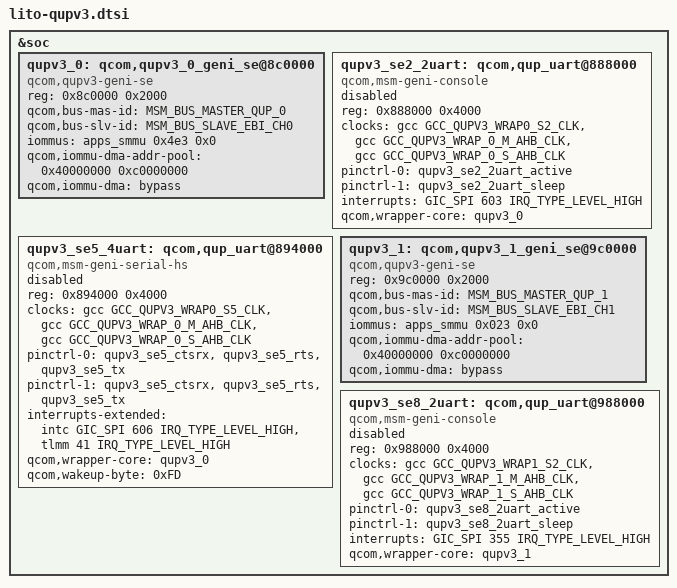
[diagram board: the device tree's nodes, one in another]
// SPDX-License-Identifier: GPL-2.0-only
/*
 * Copyright (c) 2018-2019, The Linux Foundation. All rights reserved.
 */

#include <dt-bindings/msm/msm-bus-ids.h>

&soc {
	/*QUPv3_0 */
	qupv3_0: qcom,qupv3_0_geni_se@8c0000 {
		compatible = "qcom,qupv3-geni-se";
		reg = <0x8c0000 0x2000>;
		qcom,bus-mas-id = <MSM_BUS_MASTER_QUP_0>;
		qcom,bus-slv-id = <MSM_BUS_SLAVE_EBI_CH0>;
		iommus = <&apps_smmu 0x4e3 0x0>;
		qcom,iommu-dma-addr-pool = <0x40000000 0xc0000000>;
		qcom,iommu-dma = "bypass";
	};

	/* Debug UART Instance for RUMI platform */
	qupv3_se2_2uart: qcom,qup_uart@888000 {
		compatible = "qcom,msm-geni-console";
		reg = <0x888000 0x4000>;
		reg-names = "se_phys";
		clock-names = "se-clk", "m-ahb", "s-ahb";
		clocks = <&gcc GCC_QUPV3_WRAP0_S2_CLK>,
			<&gcc GCC_QUPV3_WRAP_0_M_AHB_CLK>,
			<&gcc GCC_QUPV3_WRAP_0_S_AHB_CLK>;
		pinctrl-names = "default", "sleep";
		pinctrl-0 = <&qupv3_se2_2uart_active>;
		pinctrl-1 = <&qupv3_se2_2uart_sleep>;
		interrupts = <GIC_SPI 603 IRQ_TYPE_LEVEL_HIGH>;
		qcom,wrapper-core = <&qupv3_0>;
		status = "disabled";
	};

	/* 4-wire UART */
	qupv3_se5_4uart: qcom,qup_uart@894000 {
		compatible = "qcom,msm-geni-serial-hs";
		reg = <0x894000 0x4000>;
		reg-names = "se_phys";
		clock-names = "se-clk", "m-ahb", "s-ahb";
		clocks = <&gcc GCC_QUPV3_WRAP0_S5_CLK>,
			<&gcc GCC_QUPV3_WRAP_0_M_AHB_CLK>,
			<&gcc GCC_QUPV3_WRAP_0_S_AHB_CLK>;
		pinctrl-names = "default", "sleep";
		pinctrl-0 = <&qupv3_se5_ctsrx>, <&qupv3_se5_rts>,
						<&qupv3_se5_tx>;
		pinctrl-1 = <&qupv3_se5_ctsrx>, <&qupv3_se5_rts>,
						<&qupv3_se5_tx>;
		interrupts-extended = <&intc GIC_SPI 606 IRQ_TYPE_LEVEL_HIGH>,
				<&tlmm 41 IRQ_TYPE_LEVEL_HIGH>;
		qcom,wrapper-core = <&qupv3_0>;
		qcom,wakeup-byte = <0xFD>;
		status = "disabled";
	};

	/*QUPv3_1 */
	qupv3_1: qcom,qupv3_1_geni_se@9c0000 {
		compatible = "qcom,qupv3-geni-se";
		reg = <0x9c0000 0x2000>;
		qcom,bus-mas-id = <MSM_BUS_MASTER_QUP_1>;
		qcom,bus-slv-id = <MSM_BUS_SLAVE_EBI_CH1>;
		iommus = <&apps_smmu 0x023 0x0>;
		qcom,iommu-dma-addr-pool = <0x40000000 0xc0000000>;
		qcom,iommu-dma = "bypass";
	};

	/* 2-wire UART */
	qupv3_se8_2uart: qcom,qup_uart@988000 {
		compatible = "qcom,msm-geni-console";
		reg = <0x988000 0x4000>;
		reg-names = "se_phys";
		clock-names = "se-clk", "m-ahb", "s-ahb";
		clocks = <&gcc GCC_QUPV3_WRAP1_S2_CLK>,
			<&gcc GCC_QUPV3_WRAP_1_M_AHB_CLK>,
			<&gcc GCC_QUPV3_WRAP_1_S_AHB_CLK>;
		pinctrl-names = "default", "sleep";
		pinctrl-0 = <&qupv3_se8_2uart_active>;
		pinctrl-1 = <&qupv3_se8_2uart_sleep>;
		interrupts = <GIC_SPI 355 IRQ_TYPE_LEVEL_HIGH>;
		qcom,wrapper-core = <&qupv3_1>;
		status = "disabled";
	};
};
